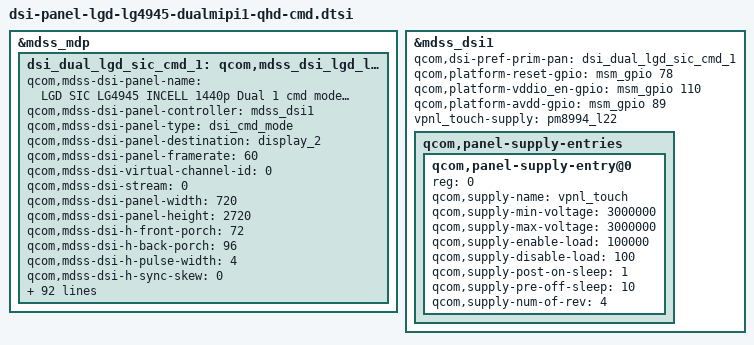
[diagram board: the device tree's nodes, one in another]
/* Copyright (c) 2014, Code Aurora Forum. All rights reserved.
 *
 * This program is free software; you can redistribute it and/or modify
 * it under the terms of the GNU General Public License version 2 and
 * only version 2 as published by the Free Software Foundation.
 *
 * This program is distributed in the hope that it will be useful,
 * but WITHOUT ANY WARRANTY; without even the implied warranty of
 * MERCHANTABILITY or FITNESS FOR A PARTICULAR PURPOSE.  See the
 * GNU General Public License for more details.
 */

&mdss_mdp {
	dsi_dual_lgd_sic_cmd_1: qcom,mdss_dsi_lgd_lg4945_1440p_mipi1_cmd {
		qcom,mdss-dsi-panel-name = "LGD SIC LG4945 INCELL 1440p Dual 1 cmd mode dsi panel";
		qcom,mdss-dsi-panel-controller = <&mdss_dsi1>;
		qcom,mdss-dsi-panel-type = "dsi_cmd_mode";
		qcom,mdss-dsi-panel-destination = "display_2";
		qcom,mdss-dsi-panel-framerate = <60>;
		qcom,mdss-dsi-virtual-channel-id = <0>;
		qcom,mdss-dsi-stream = <0>;
		qcom,mdss-dsi-panel-width = <720>;
		qcom,mdss-dsi-panel-height = <2720>;
		qcom,mdss-dsi-h-front-porch = <72>;
		qcom,mdss-dsi-h-back-porch = <96>;
		qcom,mdss-dsi-h-pulse-width = <4>;
		qcom,mdss-dsi-h-sync-skew = <0>;
		qcom,mdss-dsi-v-back-porch = <43>;
		qcom,mdss-dsi-v-front-porch = <8>;
		qcom,mdss-dsi-v-pulse-width = <1>;
		qcom,mdss-dsi-h-left-border = <0>;
		qcom,mdss-dsi-h-right-border = <0>;
		qcom,mdss-dsi-v-top-border = <0>;
		qcom,mdss-dsi-v-bottom-border = <0>;
		qcom,mdss-dsi-bpp = <24>;
		qcom,mdss-dsi-color-order = "rgb_swap_rgb";
		qcom,mdss-dsi-underflow-color = <0xff>;
		qcom,mdss-dsi-border-color = <0>;
		qcom,mdss-dsi-h-sync-pulse = <0>;
		qcom,mdss-dsi-traffic-mode = "burst_mode";
		qcom,mdss-dsi-lane-map = "lane_map_0123";
		qcom,mdss-dsi-lane-hs = <1>;
		qcom,mdss-dsi-bllp-eof-power-mode;
		qcom,mdss-dsi-bllp-power-mode;
		qcom,cmd-sync-wait-broadcast;
		qcom,cmd-sync-wait-trigger;
		qcom,mdss-dsi-lane-0-state;
		qcom,mdss-dsi-lane-1-state;
		qcom,mdss-dsi-lane-2-state;
		qcom,mdss-dsi-lane-3-state;
		qcom,mdss-dsi-hor-line-idle = <0 40 256>,
						<40 120 128>,
						<120 240 64>;
		qcom,mdss-dsi-panel-timings = [D4 38 38 00 68 5E
									3A 3A 2C 03 04 00];
		qcom,mdss-dsi-reset-sequence = <1 10>, <0 10>, <1 10>;
		qcom,mdss-dsi-t-clk-post = <0x02>;
		lge,mdss-dsi-t-clk-post_for_jdi_ab = <0x32>;
		qcom,mdss-dsi-t-clk-pre = <0x2D>;
		qcom,mdss-dsi-bl-max-level = <4095>;
		qcom,mdss-dsi-dma-trigger = "trigger_sw";
		qcom,mdss-dsi-mdp-trigger = "none";
		qcom,mdss-dsi-te-pin-select = <1>;
		qcom,mdss-dsi-wr-mem-start = <0x2c>;
		qcom,mdss-dsi-wr-mem-continue = <0x3c>;
		qcom,mdss-dsi-te-dcs-command = <1>;
		qcom,mdss-dsi-te-check-enable;
		qcom,mdss-dsi-te-using-te-pin;
		qcom,suspend-ulps-enabled;
		qcom,mdss-dsi-tx-eot-append;
		qcom,mdss-mdp-transfer-time-us = <15000>;
		/* Partial update */
		qcom,partial-update-enabled;
		qcom,partial-update-roi-merge;
		qcom,mdss-dsi-on-command = [ /*initset v0.9*/
			/* Page Address Set */
			39 01 00 00 00 00 05 2B 00 00 0A 9F
			/* Manufacturer Command Protection */
			15 01 00 00 00 00 02 B0 AC
			/* Touch timing setting to prevent tearing */
			39 01 00 00 00 00 03 44 0A 8C
			/* Tearing Effect Line on */
			15 01 00 00 00 00 02 35 00
			/* Write Control Display */
			15 01 00 00 00 00 02 53 24
			/* Write Display Brightness */
			15 01 00 00 00 00 02 51 FF
			/* Write Content Adaptive Brightness Control */
			15 01 00 00 00 00 02 55 81
			/* Display Control 1 */
			39 01 00 00 00 00 08 B3 0A 14 28 C8 1A 94 02
			/* Display Control 2 */
			39 01 00 00 00 00 0B B4 91 08 0A 0A 0A 0A 14 14 14 14
			/* Display Control 3 */
			39 01 00 00 00 00 0F B5 28 10 20 C8 22 09 09 01 01 00 68 E8 05 05
			/* Display Control 4 */
			39 01 00 00 00 00 06 B6 16 0F 00 08 0A
			/* Panel Setting */
			39 01 00 00 00 00 06 B8 60 91 A7 90 01
			/* Internal Oscillator Setting */
			39 01 00 00 00 00 03 C0 91 00
			/* Power Control 1 */
			39 01 00 00 00 00 06 C1 01 00 F0 C2 CF
			/* Power Control 2 */
			15 01 00 00 00 00 02 C2 CC
			/* Power Control 3 */
			39 01 00 00 00 00 06 C3 35 88 22 26 21
			/* Power Control 5 */
			39 01 00 00 00 00 08 C5 24 20 A0 25 14 32 02
			/* Abrupt Power Off Control */
			15 01 00 00 00 00 02 C9 9F
			/* U2 Control */
			39 01 00 00 00 00 0C CB 86 46 0F 77 06 01 16 0F 08 0A 36
			/* Touch Control */
			39 01 00 00 00 00 10 CD F0 4C 0D 3F 4F 22 22 01 0A 01 02 57 A8 64 64
			/* Positive Gamma Curve for Red */
			39 01 00 00 00 00 0E D0 00 12 1C 2B 36 3E 53 4B 41 36 2C 2C 03
			/* Negative Gamma Curve for Red */
			39 01 00 00 00 00 0E D1 00 12 1C 2B 36 3E 53 4B 41 36 2C 2C 03
			/* Positive Gamma Curve for  Green */
			39 01 00 00 00 00 0E D2 00 12 1E 2B 36 3E 51 48 3C 2C 17 08 03
			/* Negative Gamma Curve for Green */
			39 01 00 00 00 00 0E D3 00 12 1E 2B 36 3E 51 48 3C 2C 17 08 03
			/* Positive Gamma Curve for Blue */
			39 01 00 00 00 00 0E D4 00 12 1F 2C 37 3F 50 47 3A 2C 17 08 03
			/* Negative Gamma Curve for Blue */
			39 01 00 00 00 00 0E D5 00 12 1F 2C 37 3F 50 47 3A 2C 17 08 03
			/* Left Side GIP Pad Setting */
			39 01 00 00 00 00 16 D6 22 2D 4C 6E 22 22 61 65 67 69 6B 22 71 55 55 55 03 55 55 55 03
			/* Right Side GIP Pad Setting */
			39 01 00 00 00 00 16 D7 22 2D 4C 6E 22 22 60 64 66 68 6a 22 71 55 55 55 03 55 55 55 03
			/* Left Side MUX Pad Setting */
			39 01 00 00 00 00 07 D8 78 77 76 75 74 73
			/* Right Side MUX Pad Setting */
			39 01 00 00 00 00 07 D9 78 77 76 75 74 73
			/* LFD Control */
			39 01 00 00 00 00 08 CA BD BD CC 0C 00 93 00
			/* OTP1 */
			39 01 00 00 00 00 04 E8 00 00 00
			/* Image Enhancement Control */
			15 01 00 00 00 00 02 F0 62
			/* Image Enhancement Control SH */
			39 01 00 00 00 00 05 F2 01 00 04 00
			/* Image Enhancement Control CSC */
			39 01 00 00 00 00 18 F3 00 43 83 C0 FF 30 00 40 80 C0 FF 50 00 3C 7C BC FF 00 00 40 80 C0 FF
			/* Backlight Control */
			39 01 00 00 00 00 07 B9 13 00 00 78 7F 80
			/* SRE Control */
			39 01 00 00 00 00 19 FC 0F 60 75 87 A8 C0 E4 F0 00 40 70 90 A0 B0 C0 F0 00 20 40 60 80 A0 C0 E0
			/* Switchable Power Domain Control */
			39 01 00 00 00 00 03 C6 04 55
			/* Display On */
			05 01 00 00 00 00 01 29
			/* Sleep Out + 100ms */
			05 01 00 00 64 00 01 11
			];
		qcom,mdss-dsi-on-command-state = "dsi_lp_mode";
		qcom,mdss-dsi-off-command = [
			/* Display Off */
			05 01 00 00 0A 00 02 28 00
			/* Memory Option Setting */
			39 01 00 00 00 00 06 E7 00 00 00 00 00
			/* Sleep In */
			05 01 00 00 00 00 02 10 00
			/* Mail box + 105ms */
			39 01 00 00 69 00 05 CC 01 00 00 00
			];
		qcom,mdss-dsi-off-command-state = "dsi_lp_mode";
		qcom,cont-splash-enabled;

		qcom,mode-control-dsi-state = "dsi_lp_mode";
		lge,mode-change-cmds-u2-to-u1 = [
			/* Write Content Adaptive Brightness Control */
			15 01 00 00 00 00 02 55 81
			/* Page Address Set */
			39 01 00 00 00 00 05 2B 00 00 0A 9F
			/* Partial Area */
			39 01 00 00 00 00 05 30 00 A0 0A 9F
			/* Partial Mode On */
			05 01 00 00 00 00 01 12
		];
		lge,mode-change-cmds-u3-to-u1 = [
			/* Write Content Adaptive Brightness Control */
			15 01 00 00 00 00 02 55 81
			/* Memory Option Setting */
			39 01 00 00 00 00 06 E7 00 00 00 00 00
			/* Partial Area */
			39 01 00 00 00 00 05 30 00 A0 0A 9F
			/* Partial Mode On */
			05 01 00 00 00 00 01 12
		];
		lge,mode-change-cmds-u1-to-u2 = [
			/* Write Content Adaptive Brightness Control */
			15 01 00 00 00 00 02 55 00
			/* Tearing Effect Line Off */
			05 01 00 00 00 00 01 34
			/* Memory Option Setting */
			39 01 00 00 00 00 06 E7 00 00 00 30 00
			/* Page Address Set */
			39 01 00 00 00 00 05 2B 00 00 00 9F
			/* Partial Area */
			39 01 00 00 00 00 05 30 00 00 00 9F
			/* Partial Mode On + 20ms Delay */
			05 01 00 00 14 00 01 12
			/* Memory Option Setting */
			39 01 00 00 00 00 06 E7 00 00 00 00 00
		];
		lge,mode-change-cmds-u3-to-u2 = [
			/* Write Content Adaptive Brightness Control */
			15 01 00 00 00 00 02 55 00
			/* Tearing Effect Line Off */
			05 01 00 00 00 00 01 34
			/* Memory Option Setting */
			39 01 00 00 00 00 06 E7 00 00 00 00 00
			/* Page Address Set */
			39 01 00 00 00 00 05 2B 00 00 00 9F
			/* Partial Area */
			39 01 00 00 00 00 05 30 00 00 00 9F
			/* Partial Mode On + 20ms */
			05 01 00 00 14 00 01 12
		];
		lge,mode-change-cmds-u1-to-u3 = [
			/* Write Content Adaptive Brightness Control */
			15 01 00 00 00 00 02 55 81
			/* Memory Option Setting */
			39 01 00 00 00 00 06 E7 00 00 00 00 00
			/* Normmal DisplayMode On */
			05 01 00 00 00 00 01 13
		];
		lge,mode-change-cmds-u2-to-u3 = [
			/* Write Content Adaptive Brightness Control */
			15 01 00 00 00 00 02 55 81
			/* Page Address Set */
			39 01 00 00 00 00 05 2B 00 00 0A 9F
			/* Normmal DisplayMode On + 33ms */
			05 01 00 00 21 00 01 13
		];
		lge,mode-change-cmds-u3-ready = [
			/*  Memory Enable*/
			39 01 00 00 00 00 06 E7 00 00 00 30 00
			/* Page Address Set */
			39 01 00 00 00 00 05 2B 00 00 0A 9F
		];
		lge,mode-change-cmds-proximity-u2-to-u3 = [
			/* Write Content Adaptive Brightness Control */
			15 01 00 00 00 00 02 55 81
			/* Switchable Power Domain Control */
			39 01 00 00 00 00 03 C6 1B 55
			/* Page Address Set */
			39 01 00 00 00 00 05 2B 00 00 0A 9F
			/* Normmal DisplayMode On + 33ms */
			05 01 00 00 21 00 01 13
		];
		lge,mode-change-cmds-proximity-u3-to-u2 = [
			/* Write Content Adaptive Brightness Control */
			15 01 00 00 00 00 02 55 00
			/* Tearing Effect Line Off */
			05 01 00 00 00 00 01 34
			/* Memory Option Setting */
			39 01 00 00 00 00 06 E7 00 00 00 00 00
			/* Switchable Power Domain Control */
			39 01 00 00 00 00 03 C6 04 55
			/* Page Address Set */
			39 01 00 00 00 00 05 2B 00 00 00 9F
			/* Partial Area */
			39 01 00 00 00 00 05 30 00 00 00 9F
			/* Partial Mode On + 20ms */
			05 01 00 00 14 00 01 12
		];

		qcom,sre-control-dsi-state = "dsi_lp_mode";
		lge,sre-cmds-off = [
			15 01 00 00 00 00 02 55 81
		];
		lge,sre-cmds-on = [
			15 01 00 00 00 00 02 55 C1
		];

		qcom,ad-control-dsi-state = "dsi_lp_mode";
		lge,ad-cmds-off = [
		    15 01 00 00 00 00 02 55 81
		];
		lge,ad-cmds-on = [
		    15 01 00 00 00 00 02 55 80
		];
		
		qcom,img-tune-control-dsi-state = "dsi_lp_mode";
		lge,sharpness-cmds-on = [
			/* Manufacturer Command Protection */
			15 01 00 00 00 00 02 B0 AC
			39 01 00 00 00 00 05 F2 01 00 04 00
		];
		lge,color_enhancement-cmds-on = [
			/* Manufacturer Command Protection */
			15 01 00 00 00 00 02 B0 AC
			15 01 00 00 00 00 02 F0 62
			39 01 00 00 00 00 18 F3 00 43 83 C0 FF 30 00 40 80 C0 FF 50 00 3C 7C BC FF 00 00 40 80 C0 FF
		];

		qcom,blmap-size = <256>;
		qcom,blmap = <
			  0 27 27 27 27 27 27 27 27 27
			  27 27 28 28 28 29 29 29 29 30
			  30 30 31 31 32 34 35 36 38 39
			  40 42 43 44 46 47 49 51 53 55
			  57 59 61 63 65 67 69 71 73 75

			  79 83 87 91 96 100 104 108 112 116
			  120 124 128 131 136 140 145 149 153 157
			  161 165 169 173 179 185 191 197 203 209
			  215 221 227 233 239 245 252 258 265 271
			  278 284 291 297 304 310 317 323 330 339

			  348 357 366 375 383 392 401 410 419 428
			  437 445 454 463 471 480 489 498 506 515
			  524 532 541 552 564 575 587 598 610 621
			  632 644 655 667 678 692 706 720 734 748
			  761 775 789 803 817 831 844 857 871 884

			  897 910 924 937 950 963 977 990 1003 1019
			  1035 1051 1067 1083 1099 1115 1131 1147 1163 1179
			  1195 1211 1228 1244 1261 1277 1293 1310 1326 1342
			  1359 1375 1392 1408 1428 1448 1467 1487 1507 1527
			  1546 1566 1586 1606 1625 1645 1665 1685 1705 1725

			  1745 1765 1785 1805 1825 1845 1865 1885 1905 1930
			  1956 1981 2007 2032 2058 2083 2109 2134 2160 2185
			  2209 2233 2257 2280 2304 2328 2352 2376 2400 2423
			  2447 2471 2495 2523 2551 2579 2607 2635 2663 2690
			  2718 2746 2774 2802 2830 2864 2897 2931 2965 2998

			  3032 3065 3099 3133 3166 3200>;

		qcom,mdss-pan-physical-width-dimension = <71>;
		qcom,mdss-pan-physical-height-dimension = <135>;

		lge,panel_power_sequence = <
			0    /*pre_msm_dss_enable_vreg*/
			0    /*post_msm_dss_enable_vreg*/
			0    /*pre_mdss_dsi_panel_reset*/
			0    /*post_mdss_dsi_panel_reset*/
			1    /*pre_mdss_dsi_panel_power_ctrl*/
			1    /*post_mdss_dsi_panel_power_ctrl*/
			0    /*post_mdss_dsi_blank*/
			1    /*post_mdss_dsi_panel_on*/
			0    /*post_mdss_dsi_panel_off*/
			1    /*lge_mdss_dsi_event_handler*/
			1    /*lge_msm_dss_enable_vreg*/
			1    /*lge_mdss_dsi_request_gpios*/
			1    /*lge_mdss_dsi_panel_reset*/
			0    /*lge_mdss_dsi_lane_config*/
			1    /*lge_mdss_dsi_ctrl_probe*/
			1    /*lge_dsi_panel_device_register*/
			1    /*lge_mdss_panel_parse_dt*/
			0    /*lge_panel_device_create*/
			1    /*lge_mdss_fb_set_bl_brightness*/
			1    /*lge_mdss_fb_blank_unblank*/
			1    /*lge_mdss_dsi_cmdlist_commit*/
			1    /*lge_mdss_dsi_panel_init*/
			1    /*lge_dump_mdss_reg*/
			1    /*lge_mdss_xlog_tout_handler_default*/
			0    /*lge_mdss_create_xlog_debug*/
			>;
	};
};

&mdss_dsi1 {
	qcom,dsi-pref-prim-pan = <&dsi_dual_lgd_sic_cmd_1>;

	qcom,platform-reset-gpio = <&msm_gpio 78 0>;
	/* qcom,dsi-panel-bias-vreg; */
	qcom,platform-vddio_en-gpio = <&msm_gpio 110 0>;
	qcom,platform-avdd-gpio = <&msm_gpio 89 0>;

	vpnl_touch-supply =  <&pm8994_l22>;

	qcom,panel-supply-entries {
		#address-cells = <1>;
		#size-cells = <0>;

		qcom,panel-supply-entry@0 {
			reg = <0>;
			qcom,supply-name = "vpnl_touch";
			qcom,supply-min-voltage = <3000000>;
			qcom,supply-max-voltage = <3000000>;
			qcom,supply-enable-load = <100000>;
			qcom,supply-disable-load = <100>;
			qcom,supply-post-on-sleep = <1>;
			qcom,supply-pre-off-sleep = <10>;

			qcom,supply-num-of-rev = <4>;
		};
	};
};

#include "dsi-panel-lgd-lg4945-dualmipi1-qhd-cmd-rev0.dtsi"
#include "dsi-panel-lgd-lg4945-dualmipi1-qhd-cmd-rev1.dtsi"
#include "dsi-panel-lgd-lg4945-dualmipi1-qhd-cmd-rev2.dtsi"
#include "dsi-panel-lgd-lg4945-dualmipi1-qhd-cmd-rev3.dtsi"
